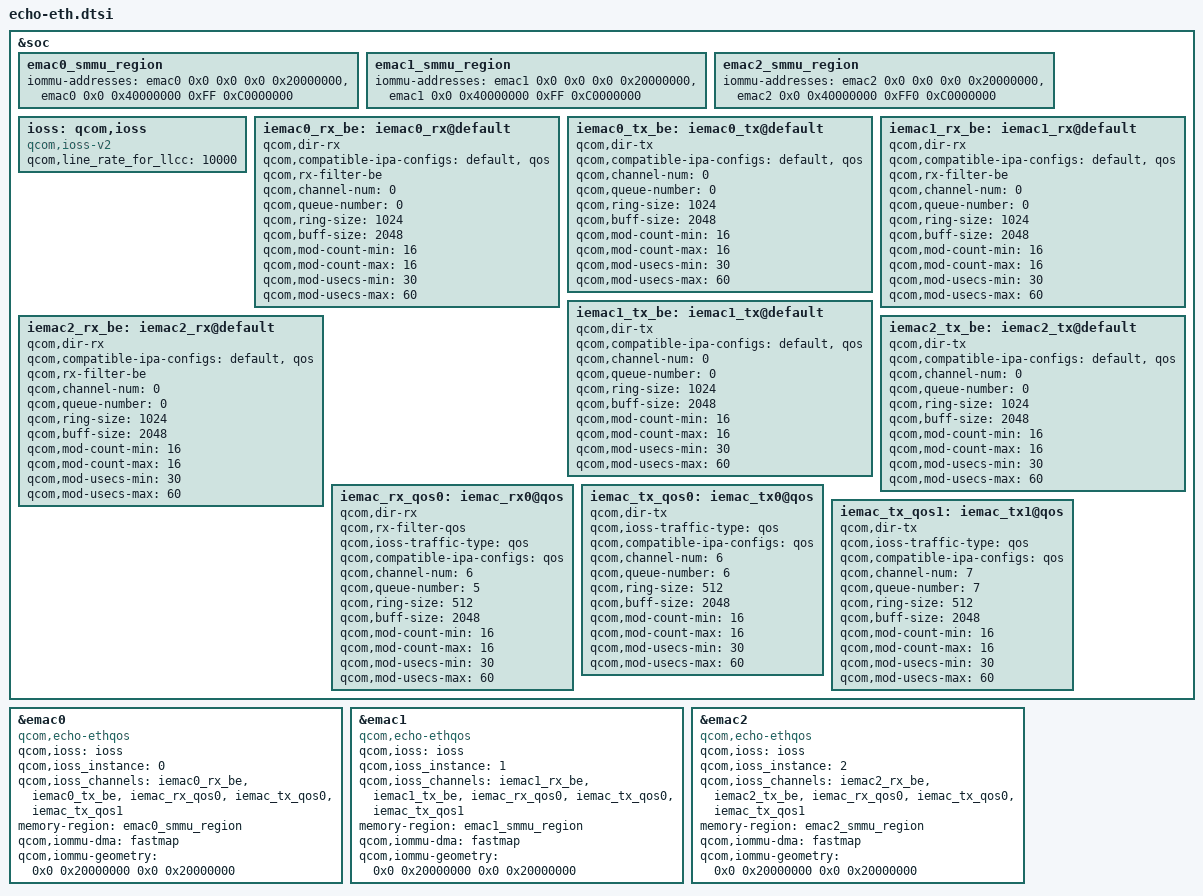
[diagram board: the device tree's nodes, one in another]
// SPDX-License-Identifier: BSD-3-Clause
/*
 * Copyright (c) Qualcomm Technologies, Inc. and/or its subsidiaries.
 */

&soc {

	emac0_smmu_region: emac0_smmu_region {
		iommu-addresses = <&emac0 0x0 0x0 0x0 0x20000000>,
				  <&emac0 0x0 0x40000000 0xFF 0xC0000000>;
	};

	emac1_smmu_region: emac1_smmu_region {
		iommu-addresses = <&emac1 0x0 0x0 0x0 0x20000000>,
				  <&emac1 0x0 0x40000000 0xFF 0xC0000000>;
	};

	emac2_smmu_region: emac2_smmu_region {
		iommu-addresses = <&emac2 0x0 0x0 0x0 0x20000000>,
				  <&emac2 0x0 0x40000000 0xFF0 0xC0000000>;
	};

	ioss: qcom,ioss {
		 compatible = "qcom,ioss-v2";
		 qcom,line_rate_for_llcc = <10000>;
	};

	iemac0_rx_be: iemac0_rx@default {
		 qcom,dir-rx;
		 qcom,compatible-ipa-configs = "default", "qos";
		 qcom,rx-filter-be;
		 qcom,channel-num = <0>;
		 qcom,queue-number = <0>;

		 qcom,ring-size = <1024>;
		 qcom,buff-size = <2048>;

		 qcom,mod-count-min = <16>;
		 qcom,mod-count-max = <16>;
		 qcom,mod-usecs-min = <30>;
		 qcom,mod-usecs-max = <60>;
	};

	iemac0_tx_be: iemac0_tx@default {
		 qcom,dir-tx;
		 qcom,compatible-ipa-configs = "default", "qos";
		 qcom,channel-num = <0>;
		 qcom,queue-number = <0>;

		 qcom,ring-size = <1024>;
		 qcom,buff-size = <2048>;

		 qcom,mod-count-min = <16>;
		 qcom,mod-count-max = <16>;
		 qcom,mod-usecs-min = <30>;
		 qcom,mod-usecs-max = <60>;
	};

	iemac1_rx_be: iemac1_rx@default {
		 qcom,dir-rx;
		 qcom,compatible-ipa-configs = "default", "qos";
		 qcom,rx-filter-be;
		 qcom,channel-num = <0>;
		 qcom,queue-number = <0>;

		 qcom,ring-size = <1024>;
		 qcom,buff-size = <2048>;

		 qcom,mod-count-min = <16>;
		 qcom,mod-count-max = <16>;
		 qcom,mod-usecs-min = <30>;
		 qcom,mod-usecs-max = <60>;
	};

	iemac1_tx_be: iemac1_tx@default {
		 qcom,dir-tx;
		 qcom,compatible-ipa-configs = "default", "qos";
		 qcom,channel-num = <0>;
		 qcom,queue-number = <0>;

		 qcom,ring-size = <1024>;
		 qcom,buff-size = <2048>;

		 qcom,mod-count-min = <16>;
		 qcom,mod-count-max = <16>;
		 qcom,mod-usecs-min = <30>;
		 qcom,mod-usecs-max = <60>;
	};

	iemac2_rx_be: iemac2_rx@default {
		 qcom,dir-rx;
		 qcom,compatible-ipa-configs = "default", "qos";
		 qcom,rx-filter-be;
		 qcom,channel-num = <0>;
		 qcom,queue-number = <0>;

		 qcom,ring-size = <1024>;
		 qcom,buff-size = <2048>;

		 qcom,mod-count-min = <16>;
		 qcom,mod-count-max = <16>;
		 qcom,mod-usecs-min = <30>;
		 qcom,mod-usecs-max = <60>;
	};

	iemac2_tx_be: iemac2_tx@default {
		 qcom,dir-tx;
		 qcom,compatible-ipa-configs = "default", "qos";
		 qcom,channel-num = <0>;
		 qcom,queue-number = <0>;

		 qcom,ring-size = <1024>;
		 qcom,buff-size = <2048>;

		 qcom,mod-count-min = <16>;
		 qcom,mod-count-max = <16>;
		 qcom,mod-usecs-min = <30>;
		 qcom,mod-usecs-max = <60>;
	};

	iemac_rx_qos0: iemac_rx0@qos {
		 qcom,dir-rx;
		 qcom,rx-filter-qos;
		 qcom,ioss-traffic-type = "qos";
		 qcom,compatible-ipa-configs = "qos";
		 qcom,channel-num = <6>;
		 qcom,queue-number = <5>;

		 qcom,ring-size = <512>;
		 qcom,buff-size = <2048>;

		 qcom,mod-count-min = <16>;
		 qcom,mod-count-max = <16>;
		 qcom,mod-usecs-min = <30>;
		 qcom,mod-usecs-max = <60>;
	};

	iemac_tx_qos0: iemac_tx0@qos {
		 qcom,dir-tx;
		 qcom,ioss-traffic-type = "qos";
		 qcom,compatible-ipa-configs = "qos";
		 qcom,channel-num = <6>;
		 qcom,queue-number = <6>;

		 qcom,ring-size = <512>;
		 qcom,buff-size = <2048>;

		 qcom,mod-count-min = <16>;
		 qcom,mod-count-max = <16>;
		 qcom,mod-usecs-min = <30>;
		 qcom,mod-usecs-max = <60>;
	};

	iemac_tx_qos1: iemac_tx1@qos {
		 qcom,dir-tx;
		 qcom,ioss-traffic-type = "qos";
		 qcom,compatible-ipa-configs = "qos";
		 qcom,channel-num = <7>;
		 qcom,queue-number = <7>;

		 qcom,ring-size = <512>;
		 qcom,buff-size = <2048>;

		 qcom,mod-count-min = <16>;
		 qcom,mod-count-max = <16>;
		 qcom,mod-usecs-min = <30>;
		 qcom,mod-usecs-max = <60>;
	};
};

&emac0 {
	compatible = "qcom,echo-ethqos", "snps,dwxgmac", "qcom,ioss-v2-device";

	qcom,ioss = <&ioss>;
	qcom,ioss_instance = <0>;
	qcom,ioss_channels = <&iemac0_rx_be>, <&iemac0_tx_be>, <&iemac_rx_qos0>, <&iemac_tx_qos0>, <&iemac_tx_qos1>;
	memory-region = <&emac0_smmu_region>;
	qcom,iommu-dma = "fastmap";
	qcom,iommu-geometry = <0x0 0x20000000 0x0 0x20000000>;
};

&emac1 {
	compatible = "qcom,echo-ethqos", "snps,dwxgmac", "qcom,ioss-v2-device";

	qcom,ioss = <&ioss>;
	qcom,ioss_instance = <1>;
	qcom,ioss_channels = <&iemac1_rx_be>, <&iemac1_tx_be>, <&iemac_rx_qos0>, <&iemac_tx_qos0>, <&iemac_tx_qos1>;
	memory-region = <&emac1_smmu_region>;
	qcom,iommu-dma = "fastmap";
	qcom,iommu-geometry = <0x0 0x20000000 0x0 0x20000000>;
};

&emac2 {
	compatible = "qcom,echo-ethqos", "snps,dwxgmac", "qcom,ioss-v2-device";
	qcom,ioss = <&ioss>;
	qcom,ioss_instance = <2>;
	qcom,ioss_channels = <&iemac2_rx_be>, <&iemac2_tx_be>, <&iemac_rx_qos0>, <&iemac_tx_qos0>, <&iemac_tx_qos1>;
	memory-region = <&emac2_smmu_region>;
	qcom,iommu-dma = "fastmap";
	qcom,iommu-geometry = <0x0 0x20000000 0x0 0x20000000>;
};
